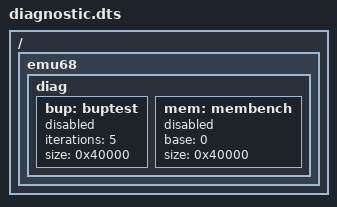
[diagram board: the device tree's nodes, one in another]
/dts-v1/;
/plugin/;

/ {
    fragment@0 {
        target-path = "/";
        __overlay__ {
            emu68 {
                diag {
                    bup: buptest {
                        status = "disabled";
                        iterations = <5>;
                        size = <0x40000>;
                    };
                };
            };
        };
    };

    fragment@1 {
        target-path = "/";
        __overlay__ {
            emu68 {
                diag {
                    mem: membench {
                        status = "disabled";
                        base = <0>;
                        size = <0x40000>;
                    };
                };
            };
        };
    };

    fragment@2 {
        target-path = "/";
        __overlay__ {
            emu68 {
                diag: diag {
                    // BOOLS are off by default
                    // debug-not-implemented
                    // enable-debug
                    // enable-disassembe
                    // dump-device-tree
                };
            };
        };
    };

    __overrides__ {
        buptest = <&bup>,"status";
        bupiter = <&bup>,"iterations:0";
        bupsize = <&bup>,"size:0";

        membench = <&mem>,"status";
        membase = <&mem>,"base:0";
        memsize = <&mem>,"size:0";

        debug_not_implemented = <&diag>,"debug-not-implemented?";
        debug = <&diag>,"enable-debug?";
        disassemble = <&diag>,"enable-disassemble?";
        dump_dt = <&diag>,"dump-device-tree?";
    };
};
